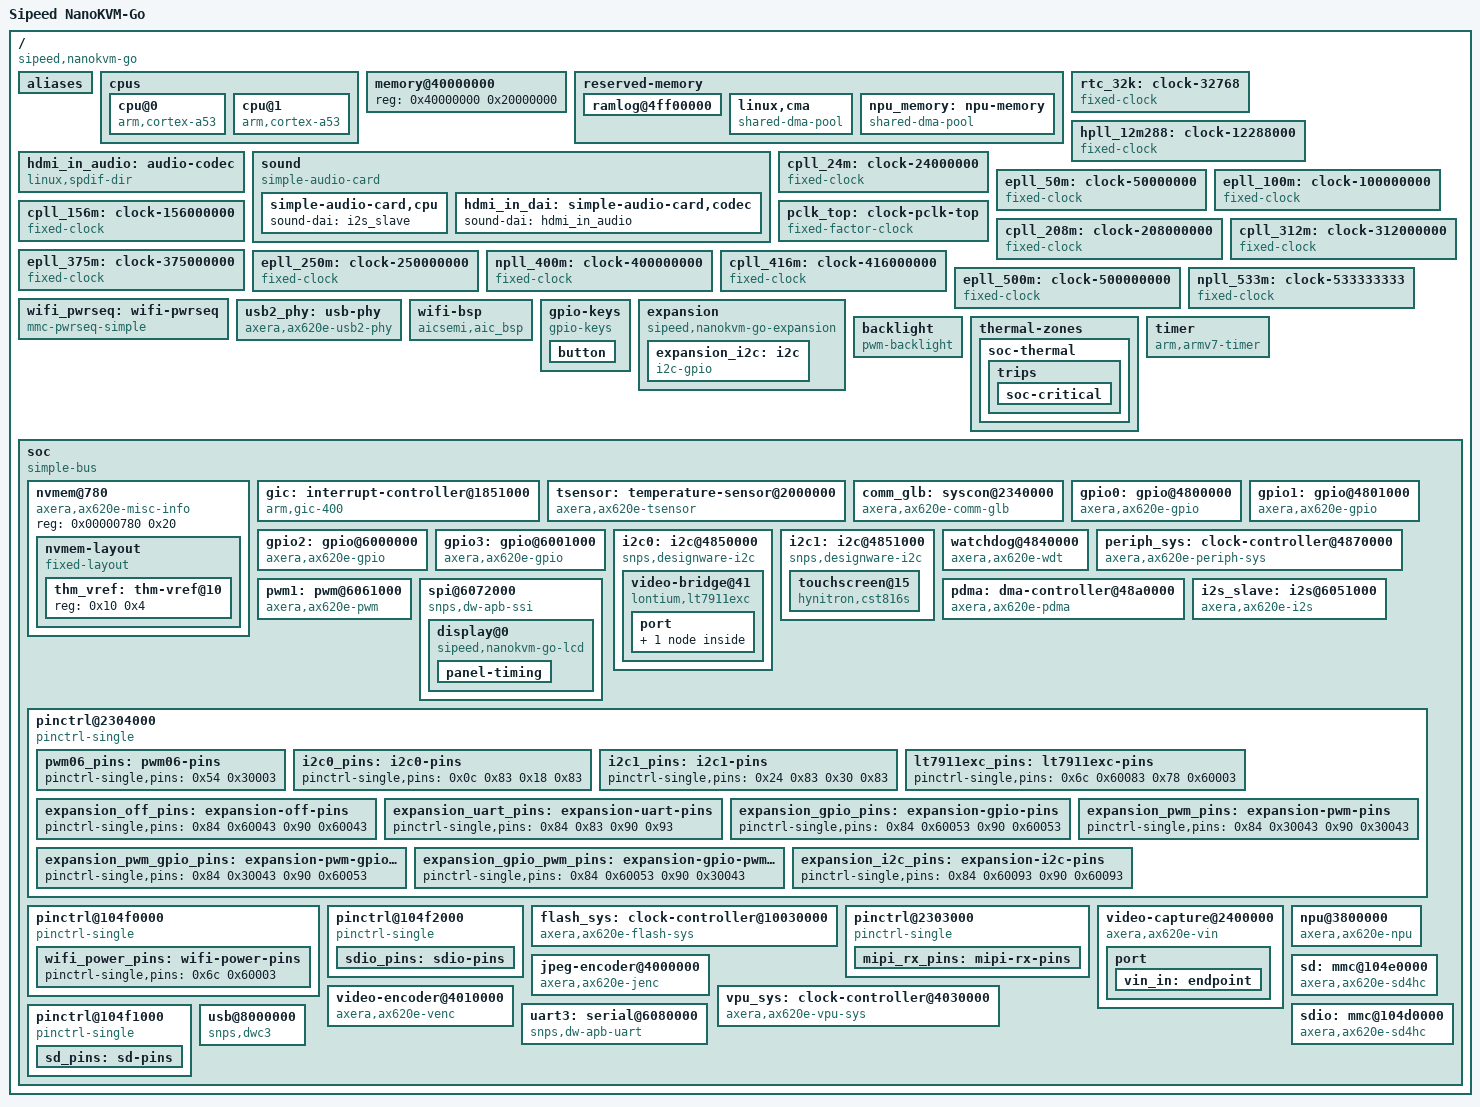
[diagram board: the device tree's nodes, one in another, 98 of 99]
// SPDX-License-Identifier: (GPL-2.0-only OR MIT)
/*
 * Sipeed NanoKVM-Go (Axera AX620QE, 2x Cortex-A53 in AArch32, 512 MiB LPDDR4
 * in package).
 */

/dts-v1/;

#include <dt-bindings/clock/axera,ax620e-comm-glb.h>
#include <dt-bindings/clock/axera,ax620e-flash-sys.h>
#include <dt-bindings/clock/axera,ax620e-periph-sys.h>
#include <dt-bindings/clock/axera,ax620e-vpu-sys.h>
#include <dt-bindings/gpio/gpio.h>
#include <dt-bindings/input/linux-event-codes.h>
#include <dt-bindings/interrupt-controller/arm-gic.h>
#include <dt-bindings/reset/axera,ax620e-comm-glb.h>
#include <dt-bindings/reset/axera,ax620e-flash-sys.h>
#include <dt-bindings/reset/axera,ax620e-periph-sys.h>
#include <dt-bindings/reset/axera,ax620e-vpu-sys.h>

/ {
	model = "Sipeed NanoKVM-Go";
	compatible = "sipeed,nanokvm-go", "axera,ax620qe";
	#address-cells = <1>;
	#size-cells = <1>;
	interrupt-parent = <&gic>;

	aliases {
		i2c0 = &i2c0;
		i2c1 = &i2c1;
		i2c2 = &expansion_i2c;
		mmc0 = &sd;
		mmc1 = &sdio;
		serial3 = &uart3;
	};

	cpus {
		#address-cells = <1>;
		#size-cells = <0>;

		cpu@0 {
			device_type = "cpu";
			compatible = "arm,cortex-a53";
			reg = <0>;
			enable-method = "axera,ax620e-smp";
		};

		cpu@1 {
			device_type = "cpu";
			compatible = "arm,cortex-a53";
			reg = <1>;
			enable-method = "axera,ax620e-smp";
		};
	};

	/*
	 * The Go+'s 512 MiB. U-Boot gives the DRAM the chip has, 256 MiB on
	 * the Go, and sizes the CMA pools below for it.
	 */
	memory@40000000 {
		device_type = "memory";
		reg = <0x40000000 0x20000000>;
	};

	reserved-memory {
		#address-cells = <1>;
		#size-cells = <1>;
		ranges;

		/* The top MiB of the first 256: in the DRAM of both boards. */
		ramlog@4ff00000 {
			reg = <0x4ff00000 0x100000>;
			no-map;
		};

		/*
		 * 4K YUYV frames are 16 MiB each: four captured frames and four
		 * worst-case JPEGs fit in 192 MiB. 256 MiB does not fit above a
		 * device tree that U-Boot leaves in place around 0x45800000.
		 */
		linux,cma {
			compatible = "shared-dma-pool";
			reusable;
			size = <0x0c000000>;
			linux,cma-default;
		};

		/*
		 * The NPU has no IOMMU: models and their inputs and outputs need
		 * contiguous memory that video capture cannot take. Movable pages
		 * use it while the NPU does not.
		 */
		npu_memory: npu-memory {
			compatible = "shared-dma-pool";
			reusable;
			size = <0x04000000>;
		};
	};

	/* PLL outputs set up by the boot firmware (no PLL driver yet). */
	rtc_32k: clock-32768 {
		compatible = "fixed-clock";
		#clock-cells = <0>;
		clock-frequency = <32768>;
		clock-output-names = "rtc_32k";
	};

	/* HPLL (1228.8 MHz, set up by the boot loader) / 100 */
	hpll_12m288: clock-12288000 {
		compatible = "fixed-clock";
		#clock-cells = <0>;
		clock-frequency = <12288000>;
		clock-output-names = "hpll_12m288";
	};

	/* The LT7911EXC passes HDMI/DP audio on as I2S, with no controls. */
	hdmi_in_audio: audio-codec {
		compatible = "linux,spdif-dir";
		#sound-dai-cells = <0>;
	};

	sound {
		compatible = "simple-audio-card";
		simple-audio-card,name = "LT7911EXC";
		simple-audio-card,format = "i2s";
		simple-audio-card,bitclock-master = <&hdmi_in_dai>;
		simple-audio-card,frame-master = <&hdmi_in_dai>;

		simple-audio-card,cpu {
			sound-dai = <&i2s_slave>;
		};

		hdmi_in_dai: simple-audio-card,codec {
			sound-dai = <&hdmi_in_audio>;
		};
	};

	cpll_24m: clock-24000000 {
		compatible = "fixed-clock";
		#clock-cells = <0>;
		clock-frequency = <24000000>;
		clock-output-names = "cpll_24m";
	};

	epll_50m: clock-50000000 {
		compatible = "fixed-clock";
		#clock-cells = <0>;
		clock-frequency = <50000000>;
		clock-output-names = "epll_50m";
	};

	epll_100m: clock-100000000 {
		compatible = "fixed-clock";
		#clock-cells = <0>;
		clock-frequency = <100000000>;
		clock-output-names = "epll_100m";
	};

	cpll_156m: clock-156000000 {
		compatible = "fixed-clock";
		#clock-cells = <0>;
		clock-frequency = <156000000>;
		clock-output-names = "cpll_156m";
	};

	/* APB clock of the peripherals (COMM_GLB 0x18 selects CPLL 208 MHz). */
	pclk_top: clock-pclk-top {
		compatible = "fixed-factor-clock";
		#clock-cells = <0>;
		clocks = <&cpll_208m>;
		clock-mult = <1>;
		clock-div = <1>;
		clock-output-names = "pclk_top";
	};

	cpll_208m: clock-208000000 {
		compatible = "fixed-clock";
		#clock-cells = <0>;
		clock-frequency = <208000000>;
		clock-output-names = "cpll_208m";
	};

	cpll_312m: clock-312000000 {
		compatible = "fixed-clock";
		#clock-cells = <0>;
		clock-frequency = <312000000>;
		clock-output-names = "cpll_312m";
	};

	epll_375m: clock-375000000 {
		compatible = "fixed-clock";
		#clock-cells = <0>;
		clock-frequency = <375000000>;
		clock-output-names = "epll_375m";
	};

	epll_250m: clock-250000000 {
		compatible = "fixed-clock";
		#clock-cells = <0>;
		clock-frequency = <250000000>;
		clock-output-names = "epll_250m";
	};

	npll_400m: clock-400000000 {
		compatible = "fixed-clock";
		#clock-cells = <0>;
		clock-frequency = <400000000>;
		clock-output-names = "npll_400m";
	};

	cpll_416m: clock-416000000 {
		compatible = "fixed-clock";
		#clock-cells = <0>;
		clock-frequency = <416000000>;
		clock-output-names = "cpll_416m";
	};

	epll_500m: clock-500000000 {
		compatible = "fixed-clock";
		#clock-cells = <0>;
		clock-frequency = <500000000>;
		clock-output-names = "epll_500m";
	};

	npll_533m: clock-533333333 {
		compatible = "fixed-clock";
		#clock-cells = <0>;
		clock-frequency = <533333333>;
		clock-output-names = "npll_533m";
	};

	/* AIC8800D80 Wi-Fi/BT: GPIO1 line 28 powers it up when high. */
	wifi_pwrseq: wifi-pwrseq {
		compatible = "mmc-pwrseq-simple";
		reset-gpios = <&gpio1 28 GPIO_ACTIVE_LOW>;
		post-power-on-delay-ms = <50>;
		pinctrl-names = "default";
		pinctrl-0 = <&wifi_power_pins>;
	};

	usb2_phy: usb-phy {
		compatible = "axera,ax620e-usb2-phy";
		axera,flash-sys = <&flash_sys>;
		clocks = <&flash_sys AX620E_FLASH_CLK_USB2_REF_ALT>;
		resets = <&flash_sys AX620E_FLASH_RST_USB2_PHY>;
		#phy-cells = <0>;
	};

	/* Node the out-of-tree AIC8800 driver looks for; power is mmc-pwrseq. */
	wifi-bsp {
		compatible = "aicsemi,aic_bsp";
	};

	gpio-keys {
		compatible = "gpio-keys";

		/* Held at power-on, U-Boot starts the stock recovery. */
		button {
			label = "BOOT";
			linux,code = <KEY_PROG1>;
			gpios = <&gpio3 2 GPIO_ACTIVE_LOW>;
		};
	};

	/*
	 * The auxiliary USB-C port's expansion lines are UART3's pads: line 0
	 * on UART3_TXD (GPIO1 line 2, PWM1 channel 0), line 1 on UART3_RXD
	 * (GPIO1 line 3, PWM1 channel 1). They start as inputs pulled down.
	 */
	expansion {
		compatible = "sipeed,nanokvm-go-expansion";
		line-gpios = <&gpio1 2 GPIO_ACTIVE_HIGH>, <&gpio1 3 GPIO_ACTIVE_HIGH>;
		pwms = <&pwm1 0 20000000 0>, <&pwm1 1 20000000 0>;
		pwm-names = "line0", "line1";
		pinctrl-names = "off", "uart", "gpio", "pwm", "pwm-gpio",
				"gpio-pwm", "i2c";
		pinctrl-0 = <&expansion_off_pins>;
		pinctrl-1 = <&expansion_uart_pins>;
		pinctrl-2 = <&expansion_gpio_pins>;
		pinctrl-3 = <&expansion_pwm_pins>;
		pinctrl-4 = <&expansion_pwm_gpio_pins>;
		pinctrl-5 = <&expansion_gpio_pwm_pins>;
		pinctrl-6 = <&expansion_i2c_pins>;

		/* Modules usually pull SDA and SCL up; 10 us is about 50 kHz. */
		expansion_i2c: i2c {
			compatible = "i2c-gpio";
			sda-gpios = <&gpio1 2 (GPIO_ACTIVE_HIGH | GPIO_OPEN_DRAIN)>;
			scl-gpios = <&gpio1 3 (GPIO_ACTIVE_HIGH | GPIO_OPEN_DRAIN)>;
			i2c-gpio,delay-us = <10>;
			#address-cells = <1>;
			#size-cells = <0>;
		};
	};

	/*
	 * PWM1 channel 2 at 25 kHz, above hearing, in 960 steps of the 24 MHz
	 * timer. Levels 0 to 100 follow CIE lightness: each step looks as much
	 * brighter as the one before.
	 */
	backlight: backlight {
		compatible = "pwm-backlight";
		pwms = <&pwm1 2 40000 0>;
		brightness-levels = <0 12 31 64 115 188 288 417 580 781 1023>;
		num-interpolated-steps = <10>;
		default-brightness-level = <100>;
	};

	thermal-zones {
		soc-thermal {
			polling-delay = <2000>;
			polling-delay-passive = <0>;
			thermal-sensors = <&tsensor>;

			trips {
				/* Shut down before the sensor resets the chip at 120 C. */
				soc-critical {
					temperature = <115000>;
					hysteresis = <0>;
					type = "critical";
				};
			};
		};
	};

	timer {
		compatible = "arm,armv7-timer";
		interrupts = <GIC_PPI 13 (GIC_CPU_MASK_SIMPLE(2) | IRQ_TYPE_LEVEL_HIGH)>,
			     <GIC_PPI 14 (GIC_CPU_MASK_SIMPLE(2) | IRQ_TYPE_LEVEL_HIGH)>,
			     <GIC_PPI 11 (GIC_CPU_MASK_SIMPLE(2) | IRQ_TYPE_LEVEL_HIGH)>,
			     <GIC_PPI 10 (GIC_CPU_MASK_SIMPLE(2) | IRQ_TYPE_LEVEL_HIGH)>;
		clock-frequency = <24000000>;
		arm,cpu-registers-not-fw-configured;
	};

	soc {
		compatible = "simple-bus";
		#address-cells = <1>;
		#size-cells = <1>;
		ranges;

		/* Only the fields after the keys the SPL keeps in IRAM too. */
		nvmem@780 {
			compatible = "axera,ax620e-misc-info";
			reg = <0x00000780 0x20>;

			nvmem-layout {
				compatible = "fixed-layout";
				#address-cells = <1>;
				#size-cells = <1>;

				thm_vref: thm-vref@10 {
					reg = <0x10 0x4>;
				};
			};
		};

		gic: interrupt-controller@1851000 {
			compatible = "arm,gic-400";
			reg = <0x01851000 0x1000>,
			      <0x01852000 0x2000>,
			      <0x01854000 0x2000>,
			      <0x01856000 0x2000>;
			interrupt-controller;
			#interrupt-cells = <3>;
			interrupts = <GIC_PPI 9 (GIC_CPU_MASK_SIMPLE(2) | IRQ_TYPE_LEVEL_HIGH)>;
		};

		tsensor: temperature-sensor@2000000 {
			compatible = "axera,ax620e-tsensor";
			reg = <0x02000000 0x1000>;
			interrupts = <GIC_SPI 61 IRQ_TYPE_LEVEL_HIGH>;
			clocks = <&comm_glb AX620E_COMM_PCLK_THM>,
				 <&comm_glb AX620E_COMM_CLK_THM>;
			resets = <&comm_glb AX620E_COMM_RST_THM_APB>,
				 <&comm_glb AX620E_COMM_RST_THM>;
			reset-names = "apb", "sensor";
			nvmem-cells = <&thm_vref>;
			nvmem-cell-names = "vref";
			#thermal-sensor-cells = <0>;
		};

		comm_glb: syscon@2340000 {
			compatible = "axera,ax620e-comm-glb", "syscon";
			reg = <0x02340000 0x1000>;
			clocks = <&cpll_24m>, <&pclk_top>;
			clock-names = "cpll_24m", "pclk_top";
			#clock-cells = <1>;
			#reset-cells = <1>;
		};

		gpio0: gpio@4800000 {
			compatible = "axera,ax620e-gpio";
			reg = <0x04800000 0x400>;
			interrupts = <GIC_SPI 114 IRQ_TYPE_LEVEL_HIGH>;
			clocks = <&periph_sys AX620E_PERIPH_CLK_GPIO0>,
				 <&periph_sys AX620E_PERIPH_PCLK_GPIO0>;
			resets = <&periph_sys AX620E_PERIPH_RST_GPIO0>;
			gpio-controller;
			#gpio-cells = <2>;
			interrupt-controller;
			#interrupt-cells = <2>;
		};

		gpio1: gpio@4801000 {
			compatible = "axera,ax620e-gpio";
			reg = <0x04801000 0x400>;
			interrupts = <GIC_SPI 115 IRQ_TYPE_LEVEL_HIGH>;
			clocks = <&periph_sys AX620E_PERIPH_CLK_GPIO1>,
				 <&periph_sys AX620E_PERIPH_PCLK_GPIO1>;
			resets = <&periph_sys AX620E_PERIPH_RST_GPIO1>;
			gpio-controller;
			#gpio-cells = <2>;
			gpio-line-names = "", "", "EXPANSION0", "EXPANSION1";
			interrupt-controller;
			#interrupt-cells = <2>;
		};

		gpio2: gpio@6000000 {
			compatible = "axera,ax620e-gpio";
			reg = <0x06000000 0x400>;
			interrupts = <GIC_SPI 116 IRQ_TYPE_LEVEL_HIGH>;
			clocks = <&periph_sys AX620E_PERIPH_CLK_GPIO2>,
				 <&periph_sys AX620E_PERIPH_PCLK_GPIO2>;
			resets = <&periph_sys AX620E_PERIPH_RST_GPIO2>;
			gpio-controller;
			#gpio-cells = <2>;
			interrupt-controller;
			#interrupt-cells = <2>;
		};

		gpio3: gpio@6001000 {
			compatible = "axera,ax620e-gpio";
			reg = <0x06001000 0x400>;
			interrupts = <GIC_SPI 117 IRQ_TYPE_LEVEL_HIGH>;
			clocks = <&periph_sys AX620E_PERIPH_CLK_GPIO3>,
				 <&periph_sys AX620E_PERIPH_PCLK_GPIO3>;
			resets = <&periph_sys AX620E_PERIPH_RST_GPIO3>;
			gpio-controller;
			#gpio-cells = <2>;
			interrupt-controller;
			#interrupt-cells = <2>;
		};

		i2c0: i2c@4850000 {
			compatible = "snps,designware-i2c";
			reg = <0x04850000 0x400>;
			interrupts = <GIC_SPI 135 IRQ_TYPE_LEVEL_HIGH>;
			clocks = <&periph_sys AX620E_PERIPH_CLK_I2C0>,
				 <&periph_sys AX620E_PERIPH_PCLK_I2C0>;
			clock-names = "ref", "pclk";
			resets = <&periph_sys AX620E_PERIPH_RST_I2C0>;
			clock-frequency = <400000>;
			i2c-sda-hold-time-ns = <500>;
			pinctrl-names = "default";
			pinctrl-0 = <&i2c0_pins>;
			#address-cells = <1>;
			#size-cells = <0>;

			video-bridge@41 {
				compatible = "lontium,lt7911exc";
				reg = <0x41>;
				interrupts-extended = <&gpio1 0 IRQ_TYPE_EDGE_FALLING>;
				reset-gpios = <&gpio1 1 GPIO_ACTIVE_LOW>;
				pinctrl-names = "default";
				pinctrl-0 = <&lt7911exc_pins>;

				port {
					lt7911exc_out: endpoint {
						remote-endpoint = <&vin_in>;
						data-lanes = <1 2 3 4>;
					};
				};
			};
		};

		/* The LCD's touch panel. */
		i2c1: i2c@4851000 {
			compatible = "snps,designware-i2c";
			reg = <0x04851000 0x400>;
			interrupts = <GIC_SPI 136 IRQ_TYPE_LEVEL_HIGH>;
			clocks = <&periph_sys AX620E_PERIPH_CLK_I2C1>,
				 <&periph_sys AX620E_PERIPH_PCLK_I2C1>;
			clock-names = "ref", "pclk";
			resets = <&periph_sys AX620E_PERIPH_RST_I2C1>;
			clock-frequency = <400000>;
			pinctrl-names = "default";
			pinctrl-0 = <&i2c1_pins>;
			#address-cells = <1>;
			#size-cells = <0>;

			/*
			 * 240x296 points over the 240x284 panel, Y from the
			 * bottom up. The pads (VI_D2, VI_D4) are GPIOs.
			 */
			touchscreen@15 {
				compatible = "hynitron,cst816s";
				reg = <0x15>;
				interrupt-parent = <&gpio0>;
				interrupts = <2 IRQ_TYPE_EDGE_FALLING>;
				reset-gpios = <&gpio0 4 GPIO_ACTIVE_LOW>;
				touchscreen-size-x = <240>;
				touchscreen-size-y = <296>;
				touchscreen-inverted-y;
			};
		};

		watchdog@4840000 {
			compatible = "axera,ax620e-wdt";
			reg = <0x04840000 0x400>;
			interrupts = <GIC_SPI 149 IRQ_TYPE_LEVEL_HIGH>;
			clocks = <&periph_sys AX620E_PERIPH_PCLK_WDT0>,
				 <&periph_sys AX620E_PERIPH_CLK_WDT0>;
			clock-names = "pclk", "wdt";
			resets = <&periph_sys AX620E_PERIPH_RST_WDT0>;
		};

		periph_sys: clock-controller@4870000 {
			compatible = "axera,ax620e-periph-sys", "syscon";
			reg = <0x04870000 0x1000>;
			clocks = <&rtc_32k>, <&cpll_24m>, <&epll_50m>,
				 <&cpll_156m>, <&cpll_208m>, <&pclk_top>,
				 <&hpll_12m288>;
			clock-names = "rtc_32k", "cpll_24m", "epll_50m",
				      "cpll_156m", "cpll_208m", "pclk_top",
				      "hpll_12m288";
			#clock-cells = <1>;
			#reset-cells = <1>;
			/*
			 * The LT7911EXC's I2S output (it drives the bit and
			 * frame clocks) into the I2S slave controller, as the
			 * vendor kernel sets it.
			 */
			axera,audio-routing = <0x00180320>;
		};

		/*
		 * The LCD's controller. SCLK and MOSI are on RGMII_TXCLK and
		 * RGMII_TXD0 (function 4), as the first boot stage leaves them;
		 * chip select, data/command and reset are GPIOs.
		 */
		pwm1: pwm@6061000 {
			compatible = "axera,ax620e-pwm";
			reg = <0x06061000 0x400>;
			clocks = <&periph_sys AX620E_PERIPH_PCLK_PWM1>,
				 <&periph_sys AX620E_PERIPH_CLK_PWM10>,
				 <&periph_sys AX620E_PERIPH_CLK_PWM11>,
				 <&periph_sys AX620E_PERIPH_CLK_PWM12>,
				 <&periph_sys AX620E_PERIPH_CLK_PWM13>;
			clock-names = "pclk", "ch0", "ch1", "ch2", "ch3";
			assigned-clocks = <&periph_sys AX620E_PERIPH_CLK_TIMER_SEL>;
			assigned-clock-parents = <&cpll_24m>;
			resets = <&periph_sys AX620E_PERIPH_RST_PWM1>;
			pinctrl-names = "default";
			pinctrl-0 = <&pwm06_pins>;
			#pwm-cells = <3>;
		};

		spi@6072000 {
			compatible = "snps,dw-apb-ssi";
			reg = <0x06072000 0x400>;
			interrupts = <GIC_SPI 153 IRQ_TYPE_LEVEL_HIGH>;
			clocks = <&periph_sys AX620E_PERIPH_CLK_SPI2>,
				 <&periph_sys AX620E_PERIPH_PCLK_SPI2>;
			clock-names = "ssi_clk", "pclk";
			resets = <&periph_sys AX620E_PERIPH_RST_SPI2>;
			reset-names = "spi";
			cs-gpios = <&gpio1 27 GPIO_ACTIVE_LOW>;
			#address-cells = <1>;
			#size-cells = <0>;

			/*
			 * ST7789P3, 240x284 of its 240x320 RAM from the top; the
			 * init sequence is the firmware file named after the
			 * first compatible.
			 */
			display@0 {
				compatible = "sipeed,nanokvm-go-lcd", "panel-mipi-dbi-spi";
				reg = <0>;
				spi-max-frequency = <52000000>;
				dc-gpios = <&gpio1 19 GPIO_ACTIVE_HIGH>;
				reset-gpios = <&gpio0 31 GPIO_ACTIVE_HIGH>;
				backlight = <&backlight>;
				width-mm = <30>;
				height-mm = <35>;

				panel-timing {
					hactive = <240>;
					vactive = <284>;
					hback-porch = <0>;
					vback-porch = <0>;
					clock-frequency = <0>;
					hfront-porch = <0>;
					hsync-len = <0>;
					vfront-porch = <0>;
					vsync-len = <0>;
				};
			};
		};

		pdma: dma-controller@48a0000 {
			compatible = "axera,ax620e-pdma";
			reg = <0x048a0000 0x1000>;
			interrupts = <GIC_SPI 112 IRQ_TYPE_LEVEL_HIGH>;
			clocks = <&periph_sys AX620E_PERIPH_ACLK_DMA>,
				 <&periph_sys AX620E_PERIPH_PCLK_DMA>;
			resets = <&periph_sys AX620E_PERIPH_RST_DMA_AXI>,
				 <&periph_sys AX620E_PERIPH_RST_DMA_APB>;
			reset-names = "axi", "apb";
			axera,periph-sys = <&periph_sys>;
			dma-channels = <16>;
			#dma-cells = <1>;
		};

		/* With no interrupt, the DesignWare I2S driver uses the DMA. */
		i2s_slave: i2s@6051000 {
			compatible = "axera,ax620e-i2s";
			reg = <0x06051000 0x400>;
			dmas = <&pdma 17>;
			dma-names = "rx";
			clocks = <&periph_sys AX620E_PERIPH_CLK_I2S_REF>,
				 <&periph_sys AX620E_PERIPH_PCLK_I2S_S>;
			clock-names = "i2sclk", "apb";
			resets = <&periph_sys AX620E_PERIPH_RST_I2S_S_APB>,
				 <&periph_sys AX620E_PERIPH_RST_I2S_S>;
			#sound-dai-cells = <0>;
		};

		/*
		 * Pad groups: one register per pin, function in [18:16],
		 * pull-up bit 7, pull-down bit 6, Schmitt trigger bit 4,
		 * drive strength [3:0].
		 */
		pinctrl@2304000 {
			compatible = "pinctrl-single";
			reg = <0x02304000 0x100>;
			#pinctrl-cells = <1>;
			pinctrl-single,register-width = <32>;
			pinctrl-single,function-mask = <0x700ff>;

			pwm06_pins: pwm06-pins {
				pinctrl-single,pins = <
					0x54 0x30003	/* UART1_TXD: PWM06 */
				>;
			};

			i2c0_pins: i2c0-pins {
				pinctrl-single,pins = <
					0x0c 0x83	/* I2C0_SCL */
					0x18 0x83	/* I2C0_SDA */
				>;
			};

			i2c1_pins: i2c1-pins {
				pinctrl-single,pins = <
					0x24 0x83	/* I2C1_SCL */
					0x30 0x83	/* I2C1_SDA */
				>;
			};

			lt7911exc_pins: lt7911exc-pins {
				pinctrl-single,pins = <
					0x6c 0x60083	/* UART2_TXD: GPIO1_A0, interrupt */
					0x78 0x60003	/* UART2_RXD: GPIO1_A1, reset */
				>;
			};

			/* The expansion lines: UART3_TXD and UART3_RXD. */
			expansion_off_pins: expansion-off-pins {
				pinctrl-single,pins = <
					0x84 0x60043	/* GPIO1_A2, pull-down */
					0x90 0x60043	/* GPIO1_A3, pull-down */
				>;
			};

			expansion_uart_pins: expansion-uart-pins {
				pinctrl-single,pins = <
					0x84 0x83	/* UART3_TXD, pull-up */
					0x90 0x93	/* UART3_RXD, pull-up, Schmitt */
				>;
			};

			expansion_gpio_pins: expansion-gpio-pins {
				pinctrl-single,pins = <
					0x84 0x60053	/* GPIO1_A2, pull-down, Schmitt */
					0x90 0x60053	/* GPIO1_A3, pull-down, Schmitt */
				>;
			};

			expansion_pwm_pins: expansion-pwm-pins {
				pinctrl-single,pins = <
					0x84 0x30043	/* PWM04, pull-down */
					0x90 0x30043	/* PWM05, pull-down */
				>;
			};

			expansion_pwm_gpio_pins: expansion-pwm-gpio-pins {
				pinctrl-single,pins = <
					0x84 0x30043	/* PWM04, pull-down */
					0x90 0x60053	/* GPIO1_A3, pull-down, Schmitt */
				>;
			};

			expansion_gpio_pwm_pins: expansion-gpio-pwm-pins {
				pinctrl-single,pins = <
					0x84 0x60053	/* GPIO1_A2, pull-down, Schmitt */
					0x90 0x30043	/* PWM05, pull-down */
				>;
			};

			expansion_i2c_pins: expansion-i2c-pins {
				pinctrl-single,pins = <
					0x84 0x60093	/* GPIO1_A2, pull-up, Schmitt */
					0x90 0x60093	/* GPIO1_A3, pull-up, Schmitt */
				>;
			};
		};

		pinctrl@104f0000 {
			compatible = "pinctrl-single";
			reg = <0x104f0000 0x80>;
			#pinctrl-cells = <1>;
			pinctrl-single,register-width = <32>;
			pinctrl-single,function-mask = <0x700ff>;

			wifi_power_pins: wifi-power-pins {
				pinctrl-single,pins = <
					0x6c 0x60003	/* EPHY_LED0: GPIO1_A28 */
				>;
			};
		};

		pinctrl@104f2000 {
			compatible = "pinctrl-single";
			reg = <0x104f2000 0x60>;
			#pinctrl-cells = <1>;
			pinctrl-single,register-width = <32>;
			pinctrl-single,function-mask = <0x700ff>;

			sdio_pins: sdio-pins {
				pinctrl-single,pins = <
					0x0c 0x83	/* SDIO_DAT0 */
					0x18 0x83	/* SDIO_DAT1 */
					0x24 0x03	/* SDIO_CLK */
					0x30 0x83	/* SDIO_CMD */
					0x3c 0x83	/* SDIO_DAT2 */
					0x48 0x83	/* SDIO_DAT3 */
				>;
			};
		};

		flash_sys: clock-controller@10030000 {
			compatible = "axera,ax620e-flash-sys";
			reg = <0x10030000 0x9000>;
			clocks = <&cpll_24m>, <&epll_100m>, <&cpll_156m>, <&cpll_208m>,
				 <&epll_250m>, <&cpll_312m>, <&npll_400m>, <&pclk_top>;
			clock-names = "cpll_24m", "epll_100m", "cpll_156m", "cpll_208m",
				      "epll_250m", "cpll_312m", "npll_400m", "pclk_top";
			#clock-cells = <1>;
			#reset-cells = <1>;
			assigned-clocks = <&flash_sys AX620E_FLASH_CLK_BUS_SEL>;
			assigned-clock-parents = <&cpll_312m>;
		};

		/* MIPI D-PHY RX pads: function 0 is the D-PHY. */
		pinctrl@2303000 {
			compatible = "pinctrl-single";
			reg = <0x02303000 0x94>;
			#pinctrl-cells = <1>;
			pinctrl-single,register-width = <32>;
			pinctrl-single,function-mask = <0x700ff>;

			mipi_rx_pins: mipi-rx-pins {
				pinctrl-single,pins = <
					0x0c 0x0 0x18 0x0	/* CDRX_L0N/P */
					0x24 0x0 0x30 0x0	/* CDRX_L1N/P */
					0x3c 0x0 0x48 0x0	/* CDRX_L2N/P */
					0x54 0x0 0x60 0x0	/* CDRX_L3N/P */
					0x6c 0x0 0x78 0x0	/* CDRX_L4N/P */
					0x84 0x0 0x90 0x0	/* CDRX_L5N/P */
				>;
			};
		};

		video-capture@2400000 {
			compatible = "axera,ax620e-vin";
			reg = <0x02400000 0x100000>,
			      <0x02500000 0x1000>,
			      <0x02600000 0x1000>,
			      <0x023f0000 0x1000>;
			reg-names = "isp", "glb", "csi", "dphy";
			interrupts = <GIC_SPI 27 IRQ_TYPE_LEVEL_HIGH>,
				     <GIC_SPI 31 IRQ_TYPE_LEVEL_HIGH>;
			interrupt-names = "isp", "csi";
			axera,comm-glb = <&comm_glb>;
			pinctrl-names = "default";
			pinctrl-0 = <&mipi_rx_pins>;

			port {
				vin_in: endpoint {
					remote-endpoint = <&lt7911exc_out>;
					data-lanes = <1 2 3 4>;
				};
			};
		};

		npu@3800000 {
			compatible = "axera,ax620e-npu";
			reg = <0x03800000 0xb0000>,
			      <0x03000000 0x280000>;
			reg-names = "regs", "ocm";
			interrupts = <GIC_SPI 38 IRQ_TYPE_EDGE_RISING>,
				     <GIC_SPI 39 IRQ_TYPE_EDGE_RISING>,
				     <GIC_SPI 42 IRQ_TYPE_EDGE_RISING>,
				     <GIC_SPI 43 IRQ_TYPE_EDGE_RISING>,
				     <GIC_SPI 40 IRQ_TYPE_EDGE_RISING>;
			interrupt-names = "normal0", "normal1", "error0", "error1",
					  "top";
			memory-region = <&npu_memory>;
		};

		jpeg-encoder@4000000 {
			compatible = "axera,ax620e-jenc";
			reg = <0x04000000 0x10000>;
			interrupts = <GIC_SPI 91 IRQ_TYPE_LEVEL_HIGH>;
			clocks = <&vpu_sys AX620E_VPU_CLK_JENC>;
			resets = <&vpu_sys AX620E_VPU_RST_JENC>;
		};

		video-encoder@4010000 {
			compatible = "axera,ax620e-venc";
			reg = <0x04010000 0x10000>;
			interrupts = <GIC_SPI 93 IRQ_TYPE_LEVEL_HIGH>;
			clocks = <&vpu_sys AX620E_VPU_CLK_VENC>;
			resets = <&vpu_sys AX620E_VPU_RST_VENC>;
		};

		vpu_sys: clock-controller@4030000 {
			compatible = "axera,ax620e-vpu-sys";
			reg = <0x04030000 0x1000>;
			clocks = <&cpll_208m>, <&cpll_312m>, <&epll_375m>,
				 <&cpll_416m>, <&epll_500m>, <&npll_533m>;
			clock-names = "cpll_208m", "cpll_312m", "epll_375m",
				      "cpll_416m", "epll_500m", "npll_533m";
			#clock-cells = <1>;
			#reset-cells = <1>;
			assigned-clocks = <&vpu_sys AX620E_VPU_CLK_JENC_SEL>,
					  <&vpu_sys AX620E_VPU_CLK_VDEC_SEL>,
					  <&vpu_sys AX620E_VPU_CLK_GLB_SEL>;
			assigned-clock-parents = <&npll_533m>, <&npll_533m>,
						 <&npll_533m>;
		};

		/* Its pads are the expansion lines, set by their driver. */
		uart3: serial@6080000 {
			compatible = "snps,dw-apb-uart";
			reg = <0x06080000 0x400>;
			interrupts = <GIC_SPI 121 IRQ_TYPE_LEVEL_HIGH>;
			clock-frequency = <208000000>;
			reg-shift = <2>;
			reg-io-width = <4>;
		};

		pinctrl@104f1000 {
			compatible = "pinctrl-single";
			reg = <0x104f1000 0x60>;
			#pinctrl-cells = <1>;
			pinctrl-single,register-width = <32>;
			pinctrl-single,function-mask = <0x700ff>;

			sd_pins: sd-pins {
				pinctrl-single,pins = <
					0x0c 0x85	/* SD_DAT0 */
					0x18 0x85	/* SD_DAT1 */
					0x24 0x05	/* SD_CLK */
					0x30 0x85	/* SD_CMD */
					0x3c 0x85	/* SD_DAT2 */
					0x48 0x85	/* SD_DAT3 */
				>;
			};
		};

		sd: mmc@104e0000 {
			compatible = "axera,ax620e-sd4hc", "cdns,sd4hc";
			reg = <0x104e0000 0x10000>;
			interrupts = <GIC_SPI 74 IRQ_TYPE_LEVEL_HIGH>;
			clocks = <&flash_sys AX620E_FLASH_CLK_SD_CARD>,
				 <&flash_sys AX620E_FLASH_ACLK_SD>,
				 <&flash_sys AX620E_FLASH_PCLK_SD>;
			resets = <&flash_sys AX620E_FLASH_RST_SD_CARD>,
				 <&flash_sys AX620E_FLASH_RST_SD_AXI>,
				 <&flash_sys AX620E_FLASH_RST_SD_APB>;
			assigned-clocks = <&flash_sys AX620E_FLASH_CLK_SD_CARD_SEL>,
					  <&flash_sys AX620E_FLASH_CLK_SD_CARD_DIV>;
			assigned-clock-parents = <&npll_400m>, <0>;
			assigned-clock-rates = <0>, <200000000>;
			pinctrl-names = "default";
			pinctrl-0 = <&sd_pins>;
			bus-width = <4>;
			max-frequency = <33333333>;
			cap-sd-highspeed;
			no-sdio;
			no-mmc;
			disable-wp;
			broken-cd;
			sdhci-caps-mask = <0x7 0x200000>;
			cdns,phy-input-delay-sd-highspeed = <2>;
			cdns,phy-input-delay-legacy = <3>;
			cdns,phy-input-delay-sd-uhs-sdr12 = <3>;
			cdns,phy-input-delay-sd-uhs-sdr25 = <2>;
			cdns,phy-input-delay-sd-uhs-sdr50 = <1>;
			cdns,phy-input-delay-sd-uhs-ddr50 = <1>;
			cdns,phy-dll-delay-sdclk = <0>;
		};

		sdio: mmc@104d0000 {
			compatible = "axera,ax620e-sd4hc", "cdns,sd4hc";
			reg = <0x104d0000 0x10000>;
			interrupts = <GIC_SPI 73 IRQ_TYPE_LEVEL_HIGH>;
			clocks = <&flash_sys AX620E_FLASH_CLK_SDIO_CARD>,
				 <&flash_sys AX620E_FLASH_ACLK_SDIO>,
				 <&flash_sys AX620E_FLASH_PCLK_SDIO>;
			resets = <&flash_sys AX620E_FLASH_RST_SDIO_CARD>,
				 <&flash_sys AX620E_FLASH_RST_SDIO_AXI>,
				 <&flash_sys AX620E_FLASH_RST_SDIO_APB>;
			assigned-clocks = <&flash_sys AX620E_FLASH_CLK_SDIO_CARD_SEL>,
					  <&flash_sys AX620E_FLASH_CLK_SDIO_CARD_DIV>;
			assigned-clock-parents = <&npll_400m>, <0>;
			assigned-clock-rates = <0>, <200000000>;
			pinctrl-names = "default";
			pinctrl-0 = <&sdio_pins>;
			mmc-pwrseq = <&wifi_pwrseq>;
			bus-width = <4>;
			max-frequency = <50000000>;
			cap-sd-highspeed;
			cap-sdio-irq;
			keep-power-in-suspend;
			non-removable;
			no-1-8-v;
			no-sd;
			no-mmc;
			disable-wp;
			sdhci-caps-mask = <0x7 0x200000>;
			cdns,phy-input-delay-sd-highspeed = <4>;
			cdns,phy-input-delay-legacy = <3>;
			cdns,phy-input-delay-sd-uhs-sdr12 = <3>;
			cdns,phy-input-delay-sd-uhs-sdr25 = <2>;
			cdns,phy-input-delay-sd-uhs-sdr50 = <1>;
			cdns,phy-input-delay-sd-uhs-ddr50 = <1>;
			cdns,phy-dll-delay-sdclk = <0>;
		};

		usb@8000000 {
			compatible = "snps,dwc3";
			reg = <0x08000000 0x100000>;
			interrupts = <GIC_SPI 76 IRQ_TYPE_LEVEL_HIGH>;
			clocks = <&flash_sys AX620E_FLASH_CLK_USB2_BUS>,
				 <&flash_sys AX620E_FLASH_CLK_USB2_REF>;
			clock-names = "bus_early", "ref";
			resets = <&flash_sys AX620E_FLASH_RST_USB2_VCC>;
			phys = <&usb2_phy>;
			phy-names = "usb2-phy";
			dr_mode = "peripheral";
			maximum-speed = "high-speed";
			phy_type = "utmi";
			snps,dis-u2-freeclk-exists-quirk;
			snps,gfladj-refclk-lpm-sel-quirk;
		};
	};
};
